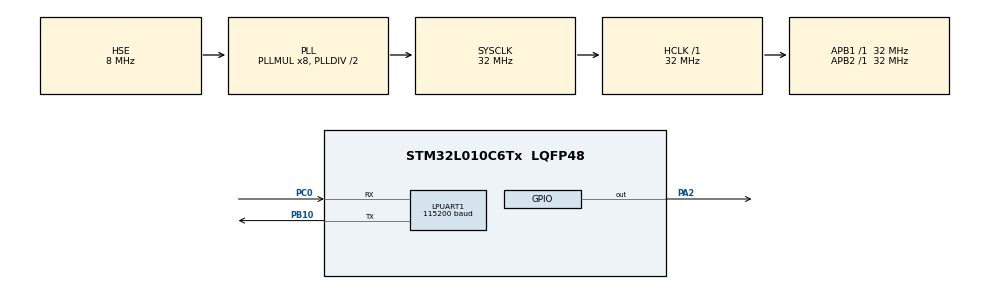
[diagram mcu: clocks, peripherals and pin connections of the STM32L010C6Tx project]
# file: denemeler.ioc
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LPUART1.BaudRate=115200
LPUART1.WordLength=UART_WORDLENGTH_8B
Mcu.Family=STM32L0
Mcu.Name=STM32L010C6Tx
Mcu.Package=LQFP48
PA13.Mode=Serial_Wire
PA13.Signal=SYS_SWDIO
PA14.Mode=Serial_Wire
PA14.Signal=SYS_SWCLK
PA2.Signal=GPIO_Output
PB10.Mode=Asynchronous
PB10.Signal=LPUART1_TX
PC0.Mode=Asynchronous
PC0.Signal=LPUART1_RX
PH0-OSC_IN.Mode=HSE-External-Oscillator
PH0-OSC_IN.Signal=RCC_OSC_IN
PH1-OSC_OUT.Mode=HSE-External-Oscillator
PH1-OSC_OUT.Signal=RCC_OSC_OUT
ProjectManager.HeapSize=0x200
ProjectManager.StackSize=0x400
ProjectManager.TargetToolchain=STM32CubeIDE
RCC.AHBFreq_Value=32000000
RCC.APB1Freq_Value=32000000
RCC.APB1TimFreq_Value=32000000
RCC.APB2Freq_Value=32000000
RCC.APB2TimFreq_Value=32000000
RCC.HCLKFreq_Value=32000000
RCC.HSE_VALUE=8000000
RCC.HSI16_VALUE=16000000
RCC.HSI_VALUE=16000000
RCC.LSE_VALUE=32768
RCC.MSI_VALUE=2097000
RCC.PLLMUL=RCC_PLLMUL_8
RCC.PLLSourceVirtual=RCC_PLLSOURCE_HSE
RCC.SYSCLKFreq_VALUE=32000000
RCC.SYSCLKSource=RCC_SYSCLKSOURCE_PLLCLK
RCC.VCOOutputFreq_Value=64000000
board=custom

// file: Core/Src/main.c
/* USER CODE BEGIN Header */
/**
  ******************************************************************************
  * @file           : main.c
  * @brief          : Main program body
  ******************************************************************************
  * @attention
  *
  * <h2><center>&copy; Copyright (c) 2021 STMicroelectronics.
  * All rights reserved.</center></h2>
  *
  * This software component is licensed by ST under BSD 3-Clause license,
  * the "License"; You may not use this file except in compliance with the
  * License. You may obtain a copy of the License at:
  *                        opensource.org/licenses/BSD-3-Clause
  *
  ******************************************************************************
  */
/* USER CODE END Header */
#include "main.h"

/* USER CODE BEGIN Includes */
#include "string.h"
/* USER CODE END Includes */

UART_HandleTypeDef hlpuart1;

void SystemClock_Config(void);
static void MX_GPIO_Init(void);
static void MX_LPUART1_UART_Init(void);

int main(void)
{

  /* MCU Configuration--------------------------------------------------------*/

  /* Reset of all peripherals, Initializes the Flash interface and the Systick. */
  HAL_Init();

  /* Configure the system clock */
  SystemClock_Config();

  /* Initialize all configured peripherals */
  MX_GPIO_Init();
  MX_LPUART1_UART_Init();
  /* USER CODE BEGIN 2 */
  //Microsecond delay

  /* USER CODE END 2 */

  /* Infinite loop */
  while (1)
  {

    /* USER CODE BEGIN 3 */
	  uint8_t veri3 [] = "1";
	      //HAL_UART_Transmit (&huart2, (uint8_t *) veri3, sizeof (veri3), 100);
	      HAL_UART_Transmit( &hlpuart1, (uint8_t *)"geliyor\r\n",10, 100);
	      HAL_Delay(2000);
	      //delay_ms(1000);
  }
  /* USER CODE END 3 */
}

void SystemClock_Config(void)
{
  RCC_OscInitTypeDef RCC_OscInitStruct = {0};
  RCC_ClkInitTypeDef RCC_ClkInitStruct = {0};
  RCC_PeriphCLKInitTypeDef PeriphClkInit = {0};

  /** Configure the main internal regulator output voltage
  */
  __HAL_PWR_VOLTAGESCALING_CONFIG(PWR_REGULATOR_VOLTAGE_SCALE1);
  /** Initializes the RCC Oscillators according to the specified parameters
  * in the RCC_OscInitTypeDef structure.
  */
  RCC_OscInitStruct.OscillatorType = RCC_OSCILLATORTYPE_HSE;
  RCC_OscInitStruct.HSEState = RCC_HSE_ON;
  RCC_OscInitStruct.PLL.PLLState = RCC_PLL_ON;
  RCC_OscInitStruct.PLL.PLLSource = RCC_PLLSOURCE_HSE;
  RCC_OscInitStruct.PLL.PLLMUL = RCC_PLLMUL_8;
  RCC_OscInitStruct.PLL.PLLDIV = RCC_PLLDIV_2;
  if (HAL_RCC_OscConfig(&RCC_OscInitStruct) != HAL_OK)
  {
    Error_Handler();
  }
  /** Initializes the CPU, AHB and APB buses clocks
  */
  RCC_ClkInitStruct.ClockType = RCC_CLOCKTYPE_HCLK|RCC_CLOCKTYPE_SYSCLK
                              |RCC_CLOCKTYPE_PCLK1|RCC_CLOCKTYPE_PCLK2;
  RCC_ClkInitStruct.SYSCLKSource = RCC_SYSCLKSOURCE_PLLCLK;
  RCC_ClkInitStruct.AHBCLKDivider = RCC_SYSCLK_DIV1;
  RCC_ClkInitStruct.APB1CLKDivider = RCC_HCLK_DIV1;
  RCC_ClkInitStruct.APB2CLKDivider = RCC_HCLK_DIV1;

  if (HAL_RCC_ClockConfig(&RCC_ClkInitStruct, FLASH_LATENCY_1) != HAL_OK)
  {
    Error_Handler();
  }
  PeriphClkInit.PeriphClockSelection = RCC_PERIPHCLK_LPUART1;
  PeriphClkInit.Lpuart1ClockSelection = RCC_LPUART1CLKSOURCE_PCLK1;
  if (HAL_RCCEx_PeriphCLKConfig(&PeriphClkInit) != HAL_OK)
  {
    Error_Handler();
  }
}

static void MX_LPUART1_UART_Init(void)
{

  hlpuart1.Instance = LPUART1;
  hlpuart1.Init.BaudRate = 115200;
  hlpuart1.Init.WordLength = UART_WORDLENGTH_8B;
  hlpuart1.Init.StopBits = UART_STOPBITS_1;
  hlpuart1.Init.Parity = UART_PARITY_NONE;
  hlpuart1.Init.Mode = UART_MODE_TX_RX;
  hlpuart1.Init.HwFlowCtl = UART_HWCONTROL_NONE;
  hlpuart1.Init.OneBitSampling = UART_ONE_BIT_SAMPLE_DISABLE;
  hlpuart1.AdvancedInit.AdvFeatureInit = UART_ADVFEATURE_NO_INIT;
  if (HAL_UART_Init(&hlpuart1) != HAL_OK)
  {
    Error_Handler();
  }

}

static void MX_GPIO_Init(void)
{
  GPIO_InitTypeDef GPIO_InitStruct = {0};

  /* GPIO Ports Clock Enable */
  __HAL_RCC_GPIOC_CLK_ENABLE();
  __HAL_RCC_GPIOH_CLK_ENABLE();
  __HAL_RCC_GPIOA_CLK_ENABLE();
  __HAL_RCC_GPIOB_CLK_ENABLE();

  /*Configure GPIO pin Output Level */
  HAL_GPIO_WritePin(GPIOA, GPIO_PIN_2, GPIO_PIN_RESET);

  /*Configure GPIO pin : PA2 */
  GPIO_InitStruct.Pin = GPIO_PIN_2;
  GPIO_InitStruct.Mode = GPIO_MODE_OUTPUT_PP;
  GPIO_InitStruct.Pull = GPIO_NOPULL;
  GPIO_InitStruct.Speed = GPIO_SPEED_FREQ_LOW;
  HAL_GPIO_Init(GPIOA, &GPIO_InitStruct);

}

void Error_Handler(void)
{
  __disable_irq();
  while (1)
  {
  }
}

/************************ (C) COPYRIGHT STMicroelectronics *****END OF FILE****/
